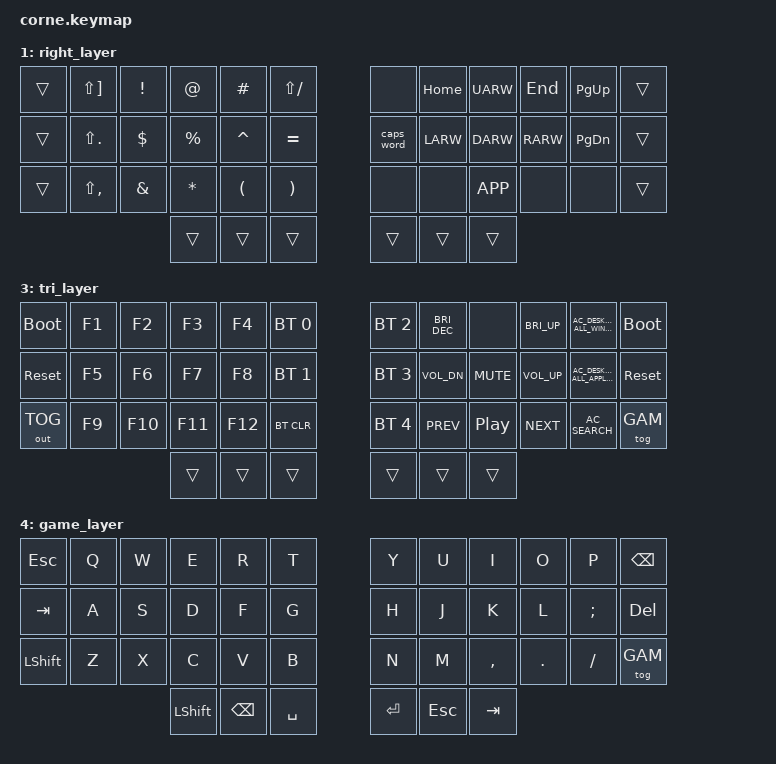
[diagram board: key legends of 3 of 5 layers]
// Copyright (c) 2022 The ZMK Contributors
// SPDX-License-Identifier: MIT

#include <behaviors.dtsi>
#include <dt-bindings/zmk/keys.h>
#include <dt-bindings/zmk/bt.h>
#include <dt-bindings/zmk/outputs.h>

// THIS IS A FRENCH LAYOUT MAPPING — macOS, layout Apple « Français »
//
// Les commentaires indiquent le caractere REELLEMENT produit par macOS,
// pas le keycode envoye. Exemple : &kp Q produit « A », &kp EQUAL produit « - ».
// Si tu modifies un binding, mets le bandeau a jour DANS LE MEME COMMIT :
// sur un keymap AZERTY-sur-QWERTY, ce commentaire est la seule doc fiable.
//
// ATTENTION : Apple « Francais » N'EST PAS l'AZERTY Windows. Pieges verifies
// a l'usage — ne pas appliquer une table AZERTY PC a cette config :
//     keycode   Apple FR        (AZERTY Windows, POUR MEMOIRE : FAUX ICI)
//     N6        §  / 6          (-)
//     N8        !  / 8          (_)
//     EQUAL     -  / _          (= / +)
//     FSLH      =  / +          (! / §)
//     NUBS      @  / #          (< / >)
//     GRAVE     <  / >          (² )

// Positions physiques (Corne 42 touches)
//   0  1  2  3  4  5      6  7  8  9 10 11
//  12 13 14 15 16 17     18 19 20 21 22 23
//  24 25 26 27 28 29     30 31 32 33 34 35
//           36 37 38     39 40 41
#define KEYS_L   0 1 2 3 4 5 12 13 14 15 16 17 24 25 26 27 28 29
#define KEYS_R   6 7 8 9 10 11 18 19 20 21 22 23 30 31 32 33 34 35
#define THUMB_L  36 37 38
#define THUMB_R  39 40 41

// Home row mods : un behavior par main, hold reserve au cross-hand
#define HRML(k1,k2,k3,k4) &hml LSHIFT k1 &hml LALT k2  &hml LCTRL k3  &hml LGUI k4
#define HRMR(k1,k2,k3,k4) &hmr RGUI k1   &hmr RCTRL k2 &hmr RALT k3   &hmr RSHIFT k4
#define RSA(k) RS(RA(k))

#define MAC 0
#define RIG 1
#define LEF 2
#define TRI 3
#define GAM 4

// Layer-taps de pouce : les pouces ne font pas de rolls, hold-preferred y est sur.
&lt {
    flavor = "hold-preferred";
    tapping-term-ms = <160>;
    quick-tap-ms = <130>;
};

/ {
    behaviors {
        // Mods main GAUCHE : le hold ne se declenche que vers la main droite
        hml: home_row_mod_left {
            compatible = "zmk,behavior-hold-tap";
            #binding-cells = <2>;
            flavor = "balanced";
            tapping-term-ms = <200>;
            quick-tap-ms = <150>;
            require-prior-idle-ms = <150>;
            hold-trigger-key-positions = <KEYS_R THUMB_R>;
            hold-trigger-on-release;
            bindings = <&kp>, <&kp>;
        };

        // Mods main DROITE : le hold ne se declenche que vers la main gauche
        hmr: home_row_mod_right {
            compatible = "zmk,behavior-hold-tap";
            #binding-cells = <2>;
            flavor = "balanced";
            tapping-term-ms = <200>;
            quick-tap-ms = <150>;
            require-prior-idle-ms = <150>;
            hold-trigger-key-positions = <KEYS_L THUMB_L>;
            hold-trigger-on-release;
            bindings = <&kp>, <&kp>;
        };
    };

    conditional_layers {
        compatible = "zmk,conditional-layers";
        tri_layer {
            if-layers = <RIG LEF>;
            then-layer = <TRI>;
        };
    };

    keymap {
        compatible = "zmk,keymap";
        default_layer {
            bindings = <
        //╭──────────┬──────────┬──────────┬──────────┬──────────┬──────────╮   ╭──────────┬──────────┬──────────┬──────────┬──────────┬──────────╮
        //│  ESC     │  A       │  Z       │  E       │  R       │  T       │   │  Y       │  U       │  I       │  O       │  P       │ BACKSPACE│
            &kp ESC     &kp Q      &kp W      &kp E      &kp R      &kp T          &kp Y      &kp U      &kp I      &kp O      &kp P      &kp BSPC
        //├──────────┼──────────┼──────────┼──────────┼──────────┼──────────┤   ├──────────┼──────────┼──────────┼──────────┼──────────┼──────────┤
        //│  TAB     │  Q ⇧     │  S ⌥     │  D ⌃     │  F ⌘     │  G       │   │  H       │  J ⌘     │  K ⌃     │  L ⌥     │  M ⇧     │  DELETE  │
            &kp TAB     HRML( A,     S,         D,         F)       &kp G          &kp H      HRMR(J,        K,           L,    SEMI)     &kp DEL
        //├──────────┼──────────┼──────────┼──────────┼──────────┼──────────┤   ├──────────┼──────────┼──────────┼──────────┼──────────┼──────────┤
        //│  SHIFT   │  W       │  X       │  C       │  V       │  B       │   │  N       │  , ?     │  ; .     │  : /     │  = +     │  - _     │
            &kp LSHIFT  &kp Z      &kp X      &kp C      &kp V      &kp B          &kp N      &kp M      &kp COMMA  &kp DOT    &kp FSLH   &kp EQUAL
        //╰──────────┴──────────┴──────────┴──────────┼──────────┼──────────┤   ├──────────┼──────────┼──────────┴──────────┴──────────┴──────────╯
        //                                            │ FN (🌐)  │ BSPC/LEF │   │  ENTER   │ ESC/RIG  │  TAB     │
                                             &kp CAPS  &lt LEF BSPC &kp SPACE     &kp ENTER  &lt RIG ESC &kp TAB
        //                                 ╰──────────┴──────────┴──────────╯   ╰──────────┴──────────┴──────────╯
        // FN : envoie CAPS_LOCK. Pour en faire une vraie touche Fn, remappe
        // Verr.maj -> Globe cote macOS (Tahoe 26) :
        //   Reglages Systeme > Clavier > bouton « Raccourcis clavier... »
        //     > « Touches de modification » (barre laterale, en bas)
        //       > menu « Selectionner un clavier » : Corne  (il doit etre connecte)
        //         > Touche Verr. maj. : Globe
        // Le reglage est PAR peripherique : les autres claviers ne bougent pas.
        // NB : &caps_word (couche RIG) applique un Shift temporaire, pas un
        // Caps Lock HID — il continue donc de fonctionner apres ce remap.
            >;
        };

        right_layer {
            bindings = <
        //╭──────────┬──────────┬──────────┬──────────┬──────────┬──────────╮   ╭──────────┬──────────┬──────────┬──────────┬──────────┬──────────╮
        //│          │  *       │  1       │  2       │  3       │  +       │   │          │  HOME    │  UP      │  END     │  PAGE UP │          │
            &trans    &kp LS(RBKT) &kp EXCL   &kp AT     &kp HASH  &kp LS(FSLH)    &none      &kp HOME   &kp UARW   &kp END    &kp PG_UP  &trans
        //├──────────┼──────────┼──────────┼──────────┼──────────┼──────────┤   ├──────────┼──────────┼──────────┼──────────┼──────────┼──────────┤
        //│          │  /       │  4       │  5       │  6       │  -       │   │ CAPS WORD│ LEFT     │ DOWN     │ RIGHT    │  PAGE DN │          │
            &trans     &kp LS(DOT) &kp DLLR   &kp PRCNT  &kp CARET  &kp EQUAL     &caps_word  &kp LARW   &kp DARW   &kp RARW   &kp PG_DN  &trans
        //├──────────┼──────────┼──────────┼──────────┼──────────┼──────────┤   ├──────────┼──────────┼──────────┼──────────┼──────────┼──────────┤
        //│          │  .       │  7       │  8       │  9       │  0       │   │          │          │  MENU    │          │          │          │
            &trans    &kp LS(COMMA) &kp AMPS  &kp ASTRK  &kp LPAR   &kp RPAR       &none      &none     &kp K_APP   &none      &none      &trans
        //╰──────────┴──────────┴──────────┴──────────┼──────────┼──────────┤   ├──────────┼──────────┼──────────┴──────────┴──────────┴──────────╯
                                              &trans     &trans     &trans         &trans     &trans     &trans
        //                                 ╰──────────┴──────────┴──────────╯   ╰──────────┴──────────┴──────────╯
            >;
        };

        left_layer {
            bindings = <
        //╭──────────┬──────────┬──────────┬──────────┬──────────┬──────────╮   ╭──────────┬──────────┬──────────┬──────────┬──────────┬──────────╮
        //│          │  &       │  é       │  "       │  '       │  (       │   │  )       │  è       │  !       │  ç       │  à       │          │
            &trans      &kp N1     &kp N2     &kp N3     &kp N4     &kp N5        &kp MINUS   &kp N7     &kp N8     &kp N9     &kp N0     &trans
        //├──────────┼──────────┼──────────┼──────────┼──────────┼──────────┤   ├──────────┼──────────┼──────────┼──────────┼──────────┼──────────┤
        //│          │  ` ⇧     │  / ⌥     │  # ⌃     │  @ ⌘     │  {       │   │  }       │  _ ⌘     │  ^ ⌃     │  | ⌥     │  $ ⇧     │          │
            &trans      HRML(BSLH, LS(DOT),   LS(NUBS),  NUBS)     &kp RA(N5)  &kp RA(MINUS) HRMR(LS(EQUAL), LBKT,  RSA(L),    RBKT)      &trans
        //├──────────┼──────────┼──────────┼──────────┼──────────┼──────────┤   ├──────────┼──────────┼──────────┼──────────┼──────────┼──────────┤
        //│          │  ù       │  \       │  <       │  >       │  [       │   │  ]       │  ~       │  %       │  °       │  €       │          │
            &trans    &kp SQT &kp RSA(DOT) &kp GRAVE &kp LS(GRAVE) &kp RSA(N5) &kp RSA(MINUS) &kp RA(N) &kp LS(SQT) &kp LS(MINUS) &kp RA(RBKT) &trans
        //╰──────────┴──────────┴──────────┴──────────┼──────────┼──────────┤   ├──────────┼──────────┼──────────┴──────────┴──────────┴──────────╯
                                              &trans     &trans     &trans         &trans     &trans     &trans
        //                                 ╰──────────┴──────────┴──────────╯   ╰──────────┴──────────┴──────────╯
        // Trema ¨ (e i u) : SHIFT + la touche ^ (le SHIFT du layer de base reste actif ici).
            >;
        };

        tri_layer {
            bindings = <
        //╭──────────┬──────────┬──────────┬──────────┬──────────┬──────────╮   ╭──────────┬──────────┬──────────┬───────────┬──────────┬──────────╮
        //│ BOOTLOAD │  F1      │  F2      │  F3      │  F4      │ PROFILE 0│   │ PROFILE 2│ DEC BR   │          │   INC BR  │  WINDOWS │ BOOTLOAD │
           &bootloader &kp F1     &kp F2     &kp F3     &kp F4   &bt BT_SEL 0   &bt BT_SEL 2 &kp C_BRI_DEC &none &kp C_BRI_UP  &kp C_AC_DESKTOP_SHOW_ALL_WINDOWS     &bootloader
        //├──────────┼──────────┼──────────┼──────────┼──────────┼──────────┤   ├──────────┼──────────┼──────────┼───────────┼──────────┼──────────┤
        //│ RESET    │  F5      │  F6      │  F7      │  F8      │ PROFILE 1│   │ PROFILE 3│ VOL DOWN │ VOL MUTE │  VOL UP   │  APPS    │ RESET    │
           &sys_reset  &kp F5     &kp F6     &kp F7     &kp F8   &bt BT_SEL 1   &bt BT_SEL 3 &kp C_VOL_DN &kp C_MUTE &kp C_VOL_UP &kp C_AC_DESKTOP_SHOW_ALL_APPLICATIONS   &sys_reset
        //├──────────┼──────────┼──────────┼──────────┼──────────┼──────────┤   ├──────────┼──────────┼──────────┼───────────┼──────────┼──────────┤
        //│ USB/BT   │  F9      │  F10     │  F11     │  F12     │  CLEAR BT│   │ PROFILE 4│ PREVSONG │ PLAY PAU │  NEXTSONG │  SEARCH  │  GAMING  │
          &out OUT_TOG &kp F9     &kp F10    &kp F11    &kp F12    &bt BT_CLR   &bt BT_SEL 4 &kp C_PREV &kp C_PP   &kp C_NEXT &kp C_AC_SEARCH  &tog GAM
        //╰──────────┴──────────┴──────────┴──────────┼──────────┼──────────┤   ├──────────┼──────────┼──────────┴───────────┴──────────┴──────────╯
                                              &trans     &trans     &trans         &trans     &trans     &trans
        //                                 ╰──────────┴──────────┴──────────╯   ╰──────────┴──────────┴──────────╯
        // GAMING (coin bas droit) : bascule vers le game_layer. Cette couche exige
        // les DEUX pouces (RIG + LEF), donc aucune activation accidentelle possible.
        // Pour en sortir : meme position (coin bas droit) dans le game_layer.
            >;
        };

        // Couche gaming : ni home row mods ni layer-taps.
        // Maintenir une touche en jeu declencherait un hold parasite permanent.
        game_layer {
            bindings = <
        //╭──────────┬──────────┬──────────┬──────────┬──────────┬──────────╮   ╭──────────┬──────────┬──────────┬──────────┬──────────┬──────────╮
        //│  ESC     │  A       │  Z       │  E       │  R       │  T       │   │  Y       │  U       │  I       │  O       │  P       │ BACKSPACE│
            &kp ESC     &kp Q      &kp W      &kp E      &kp R      &kp T          &kp Y      &kp U      &kp I      &kp O      &kp P      &kp BSPC
        //├──────────┼──────────┼──────────┼──────────┼──────────┼──────────┤   ├──────────┼──────────┼──────────┼──────────┼──────────┼──────────┤
        //│  TAB     │  Q       │  S       │  D       │  F       │  G       │   │  H       │  J       │  K       │  L       │  M       │  DELETE  │
            &kp TAB     &kp A      &kp S      &kp D      &kp F      &kp G          &kp H      &kp J      &kp K      &kp L      &kp SEMI   &kp DEL
        //├──────────┼──────────┼──────────┼──────────┼──────────┼──────────┤   ├──────────┼──────────┼──────────┼──────────┼──────────┼──────────┤
        //│  SHIFT   │  W       │  X       │  C       │  V       │  B       │   │  N       │  , ?     │  ; .     │  : /     │  ! §     │ < GAMING │
            &kp LSHIFT  &kp Z      &kp X      &kp C      &kp V      &kp B          &kp N      &kp M      &kp COMMA  &kp DOT    &kp FSLH   &tog GAM
        //╰──────────┴──────────┴──────────┴──────────┼──────────┼──────────┤   ├──────────┼──────────┼──────────┴──────────┴──────────┴──────────╯
        //                                            │  SHIFT   │  BSPC    │   │  ENTER   │  ESC     │  TAB     │
                                            &kp LSHIFT  &kp BSPC   &kp SPACE     &kp ENTER  &kp ESC    &kp TAB
        //                                 ╰──────────┴──────────┴──────────╯   ╰──────────┴──────────┴──────────╯
        // SHIFT au pouce gauche = sprint accessible sans quitter ZQSD.
            >;
        };
    };
};
